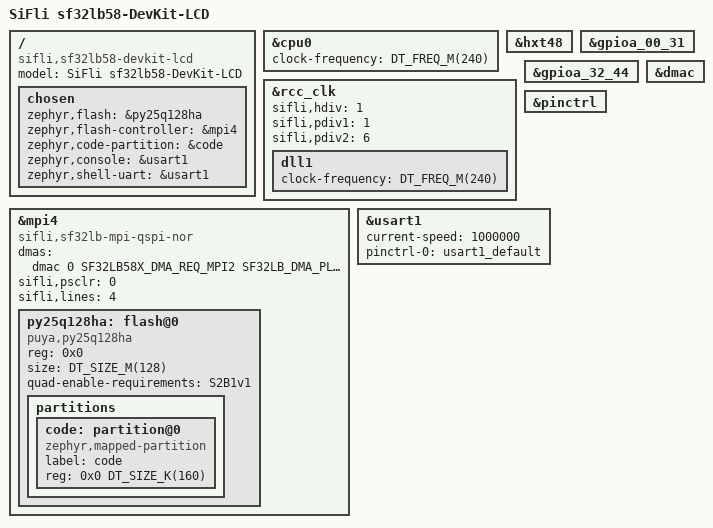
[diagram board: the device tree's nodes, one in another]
/*
 * Copyright (c) 2026 Qingsong Gou <gouqs@hotmail.com>
 * SPDX-License-Identifier: Apache-2.0
 */

/dts-v1/;

#include <sifli/sf32lb58x/sf32lb58x.dtsi>
#include <sifli/sf32lb58x/sf32lb58x-ram012.dtsi>
#include <zephyr/dt-bindings/dma/sf32lb58x-dma.h>
#include <zephyr/dt-bindings/gpio/gpio.h>
#include <zephyr/dt-bindings/input/input-event-codes.h>

#include "sf32lb58_devkit_lcd-pinctrl.dtsi"

/ {
	model = "SiFli sf32lb58-DevKit-LCD";
	compatible = "sifli,sf32lb58-devkit-lcd";

	chosen {
		zephyr,flash = &py25q128ha;
		zephyr,flash-controller = &mpi4;
		zephyr,code-partition = &code;
		zephyr,console = &usart1;
		zephyr,shell-uart = &usart1;
	};
};

&cpu0 {
	clock-frequency = <DT_FREQ_M(240)>;
};

&hxt48 {
	status = "okay";
};

&rcc_clk {
	status = "okay";

	sifli,hdiv = <1>;
	sifli,pdiv1 = <1>;
	sifli,pdiv2 = <6>;

	dll1 {
		status = "okay";
		clock-frequency = <DT_FREQ_M(240)>;
	};
};

&gpioa_00_31 {
	status = "okay";
};

&gpioa_32_44 {
	status = "okay";
};

&dmac {
	status = "okay";
};

&mpi4 {
	compatible = "sifli,sf32lb-mpi-qspi-nor";
	dmas = <&dmac 0 SF32LB58X_DMA_REQ_MPI2 SF32LB_DMA_PL_MEDIUM>;
	sifli,psclr = <0>;
	sifli,lines = <4>;
	status = "okay";

	py25q128ha: flash@0 {
		compatible = "puya,py25q128ha", "jedec,qspi-nor", "soc-nv-flash";
		reg = <0x0>;
		size = <DT_SIZE_M(128)>;
		quad-enable-requirements = "S2B1v1";

		partitions {
			#address-cells = <1>;
			#size-cells = <1>;
			ranges;

			code: partition@0 {
				compatible = "zephyr,mapped-partition";
				label = "code";
				reg = <0x0 DT_SIZE_K(160)>;
			};
		};
	};
};

&pinctrl {
	status = "okay";
};

&usart1 {
	status = "okay";
	current-speed = <1000000>;
	pinctrl-0 = <&usart1_default>;
	pinctrl-names = "default";
};
